# CH32L103 register map
Vendor: WCH Ltd.; File version: 1.0
Registers are 32-bit, read-write, reset 0x0 unless marked. A register's access mark holds for its fields unless they carry their own. Offsets are from the block's base; [hi:lo] are bit positions.

## SYSTICK — Systick registers, 64-bit downcounter for QingKeV4
Base 0xE000F000
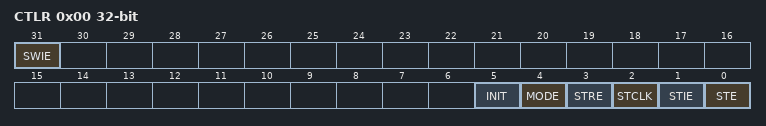
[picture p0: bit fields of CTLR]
0x00 CTLR — System count control register
  [31] SWIE — Software interrupt enable
  [5] INIT — Counter initial value update
  [4] MODE — Counter mode
    0=Upcount; 1=Downcount
  [3] STRE — Auto reload count enable bit
  [2] STCLK — Counter system clock sourse selection bit
    0=HCLK_DIV8 (HCLK/8); 1=HCLK
  [1] STIE — Counter interrupt enable control bit
  [0] STE — Counter enable control bit
0x04 SR — System count status register
  [0] CNTIF — Count value compare flag
0x08 CNT 64-bit (reset mask 0xFFFFFFFF) — System counter register
0x08 CNTL — System counter register, lower 32-bit
0x10 CMP 64-bit (reset mask 0xFFFFFFFF) — System count compare register
0x10 CMPL — System count compare register, lower 32-bit

## LPTIM — Low-power timer
Base 0x40007C00
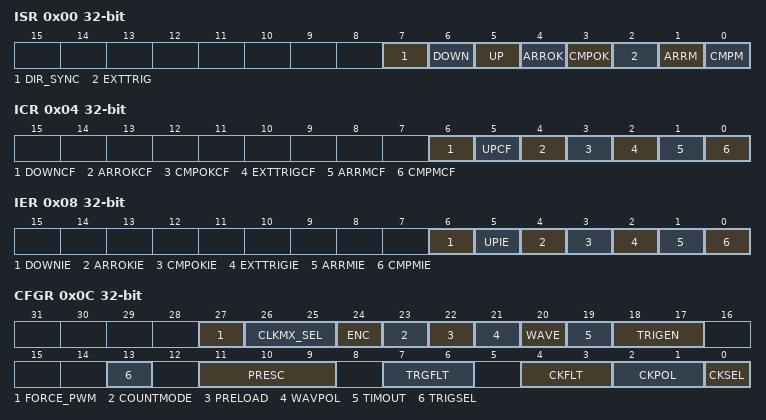
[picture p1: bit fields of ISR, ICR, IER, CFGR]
0x00 ISR ro — interrupt status register
  [7] DIR_SYNC — direction of count
  [6] DOWN — count down
  [5] UP — count-up
  [4] ARROK — Aoto-reload register data update successfully
  [3] CMPOK — compare register data update successfully
  [2] EXTTRIG — Edge event are triggerd externally
  [1] ARRM — DATA of Aoto-reload register and LPTIM_CNT match
  [0] CMPM — DATA of compare register and LPTIM_CNT match
0x04 ICR wo — interrupt clear register
  [6] DOWNCF — clear down flag
  [5] UPCF — clear up flag
  [4] ARROKCF — clear Aoto-reload register data update flag
  [3] CMPOKCF — clear compare register data update flag
  [2] EXTTRIGCF — clear Edge event are triggerd externally flag
  [1] ARRMCF — clear Aoto-reload register match flag
  [0] CMPMCF — clear compare register match flag
0x08 IER — interrupt enable register
  [6] DOWNIE — Down interrupt enable
  [5] UPIE — UP interrupt enable
  [4] ARROKIE — Aoto-reload register data update successfully interrupts enable
  [3] CMPOKIE — compare register data update successfully interrupts enable
  [2] EXTTRIGIE — Edge event are triggerd externally successfully interrupts enable
  [1] ARRMIE — Aoto-reload register match successfully interrupts enable
  [0] CMPMIE — compare register match successfully interrupts enable
0x0C CFGR — configuration register
  [27] FORCE_PWM — Forcing pwm output
  [26:25] CLKMX_SEL — clock selection
  [24] ENC — coder mode
  [23] COUNTMODE — count clock selection
  [22] PRELOAD — update mode control
  [21] WAVPOL — PWM polarity
  [20] WAVE — PWM
  [19] TIMOUT — TIMEOUT control
  [18:17] TRIGEN — trigger configuration
  [13] TRIGSEL — trigger source selection
  [11:9] PRESC — prescaler configuration
  [7:6] TRGFLT — digital filter for flip-flops
  [4:3] CKFLT — digital filter for ex-clock
  [2:1] CKPOL — configure effective edges
  [0] CKSEL — effective edge configuration
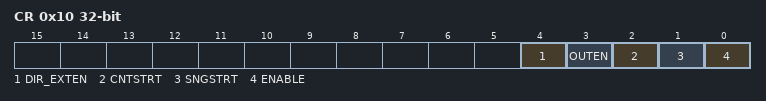
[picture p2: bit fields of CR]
0x10 CR — control register
  [4] DIR_EXTEN — externally trigger count direction enable
  [3] OUTEN — pwm output enable
  [2] CNTSTRT — start in continuous mode
  [1] SNGSTRT — start in one trigger mode
  [0] ENABLE — timer enable
0x14 CMP — compare register
  [15:0] CMP — compare value
0x18 ARR — aoto-reload register
  [15:0] ARR — aoto-reload count value
0x1C CNT — COUNT register
  [15:0] COUNT — Timer count value

## USBPD — USBPD control register
Base 0x40027000
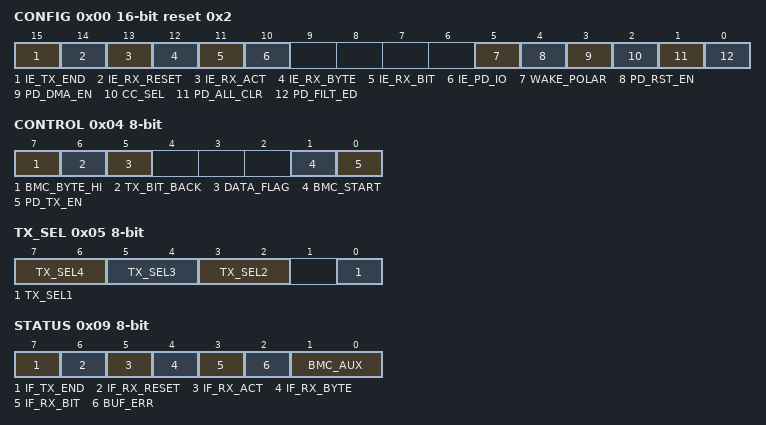
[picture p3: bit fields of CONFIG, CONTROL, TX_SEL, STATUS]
0x00 CONFIG 16-bit reset 0x2 — PD configuration register
  [15] IE_TX_END — end of send interrupt enable
  [14] IE_RX_RESET — receive reset interrupt enable
  [13] IE_RX_ACT — receive finished interrupt enable
  [12] IE_RX_BYTE — receive byte interrupt enable
  [11] IE_RX_BIT — receive bit interrupt enable
  [10] IE_PD_IO — PD port interrupt enable
  [5] WAKE_POLAR — wake-up level
  [4] PD_RST_EN — reset enable
  [3] PD_DMA_EN — PD_DMA enable
  [2] CC_SEL — communication port selection
  [1] PD_ALL_CLR — clear all interrupt enable
  [0] PD_FILT_ED — PD pin input filter enable
0x02 BMC_CLK_CNT 16-bit — BMC sample clock counter
  [8:0] BMC_CLK_CNT — BMC sent/receive sample clock counter
0x04 CONTROL 8-bit — sent/receive enable register
  [7] BMC_BYTE_HI — sent/receive half bytes status of data
  [6] TX_BIT_BACK — sent code status of bit
  [5] DATA_FLAG — data cache valid flag
  [1] BMC_START — BMC send a start signal
  [0] PD_TX_EN — sent/receive enable
0x05 TX_SEL 8-bit — PD send sop selection register
  [7:6] TX_SEL4 — PD send type selection
  [5:4] TX_SEL3 — PD send type selection
  [3:2] TX_SEL2 — PD send type selection
  [0] TX_SEL1 — PD send type selection
0x06 BMC_TX_SZ 16-bit — Total length sent
  [8:0] BMC_TX_SZ
0x08 DATA_BUF 8-bit — DMA buffer data register
  [7:0] DATA_BUF — DMA DATA_BUFFER
0x09 STATUS 8-bit — PD interrupt flag register
  [7] IF_TX_END — Transmission completed interrupt flag
  [6] IF_RX_RESET — Receive reset interrupt flag
  [5] IF_RX_ACT — Receive completed interrupt flag
  [4] IF_RX_BYTE — Receive byte/SOP interrupt flag
  [3] IF_RX_BIT — Receive BIT/5BIT interrupt flag
  [2] BUF_ERR — BUFFER/DMA error interrupt flag
  [1:0] BMC_AUX — Indicating the current state
0x0A BMC_BYTE_CNT 16-bit ro — byte count register
  [8:0] BMC_BYTE_CNT
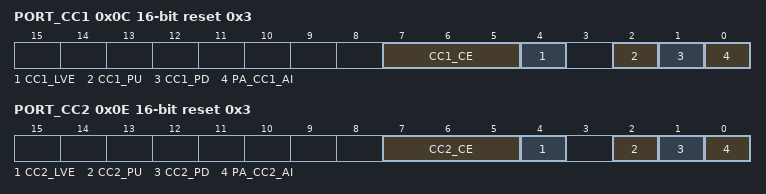
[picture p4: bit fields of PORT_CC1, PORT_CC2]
0x0C PORT_CC1 16-bit reset 0x3 — port control register
  [7:5] CC1_CE — Enable port voltage comparator
  [4] CC1_LVE — port output lower voltage enable
  [2] CC1_PU — port pull-up current enable
  [1] CC1_PD — port pull-down resistor enable
  [0] PA_CC1_AI — port comparator simulates input
0x0E PORT_CC2 16-bit reset 0x3 — port control register
  [7:5] CC2_CE — Enable port voltage comparator
  [4] CC2_LVE — port output lower voltage enable
  [2] CC2_PU — port pull-up current enable
  [1] CC2_PD — port pull-down resistor enable
  [0] PA_CC2_AI — port comparator simulates input
0x10 DMA 16-bit — DMA cache start address register
  [15:0] USBPD_DMA_ADDR — USBPD_DMA cache address
